# NUC1xx_registers register map
File version: 0.1
Registers are 32-bit, read-write, reset 0x0 unless marked. A register's access mark holds for its fields unless they carry their own. Offsets are from the block's base; [hi:lo] are bit positions; lines under a group give offsets from that group; {n}, {i} and the like mark numbered series.

## GPIO — Registers group
Base 0x50004180
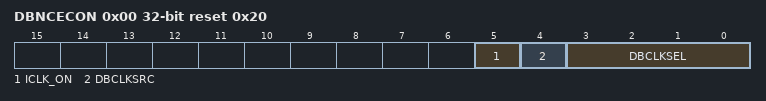
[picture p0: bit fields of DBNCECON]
0x00 DBNCECON reset 0x20 (reset mask 0xFFFFFFDF) — External Interrupt De-bounce Control
  [5] ICLK_ON — Interrupt clock On mode Set this bit to 0 will disable the interrupt generate circuit clock, if the pin[n] interrupt is disabled 1 = Interrupt generated circuit clock always enable 0 = Disable the clock if the GPIOA/B/C/D/E[n] interrupt is disabled
  [4] DBCLKSRC — De-bounce counter clock source select 1 = De-bounce counter clock source is the internal 10 KHz clock 0 = De-bounce counter clock source is the HCLK
  [3:0] DBCLKSEL — De-bounce sampling cycle selection DBCLKSEL Description 0 Sample interrupt input once per 1 clocks 1 Sample interrupt input once per 2 clocks 2 Sample interrupt input once per 4 clocks 3 Sample interrupt input once per 8 clocks 4 Sample interrupt input once per 16 clocks 5 Sample interrupt input once per 32 clocks 6 Sample interrupt input once per 64 clocks 7 Sample interrupt input once per 128 clocks 8 Sample interrupt input once per 256 clocks 9 Sample interrupt input once per 2*256 clocks 10 Sample interrupt input once per 4*256clocks 11 Sample interrupt input once per 8*256 clocks 12 Sample interrupt input once per 16*256 clocks 13 Sample interrupt input once per 32*256 clocks 14 Sample interrupt input once per 64*256 clocks 15 Sample interrupt input once per 128*256 clocks

## GPA_BITS — Registers group
Base 0x50004200
Same registers: GPB_BITS 0x50004240, GPC_BITS 0x50004280, GPD_BITS 0x500042C0, GPE_BITS 0x50004300
{0x0+4i} DOUT[{i}] (i=0..15) reset 0x1 — GPIO Port Pin I/O Bit Output Control
  [0] DOUT — GPIOxx I/O Pin Bit Output Control Set this bit can control one GPIO pin output value For example: write GPIOx0_DOUT will reflect the written value to bit GPIOx_DOUT[0], read GPIOx0_DOUT will return the value of GPIOx_PIN[0].
    0=low (Set corresponding GPIO bit to low); 1=high (Set corresponding GPIO bit to high)

## WDT — Registers group
Base 0x40004000
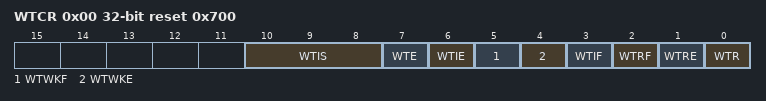
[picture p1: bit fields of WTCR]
0x00 WTCR reset 0x700 (reset mask 0xFFFFF8FF) — Watchdog Timer Control Register
  [10:8] WTIS — Watchdog Timer Interval Select (write protection bit) These three bits select the timeout interval for the Watchdog timer. WTIS Timeout Interval Selection Interrupt Period WTR Timeout Interval (WDT_CLK=12MHz) 000 2^4 * WDT_CLK (2^4 + 1024) * WDT_CLK 1.33 us ~ 86.67 us 001 2^6 * WDT_CLK (2^6 + 1024) * WDT_CLK 5.33 us ~ 90.67 us 010 2^8 * WDT_CLK (2^8 + 1024) * WDT_CLK 21.33 us ~ 106.67 us 011 2^10 * WDT_CLK (2^10 + 1024) * WDT_CLK 85.33 us ~ 170.67 us 100 2^12 * WDT_CLK (2^12 + 1024) * WDT_CLK 341.33 us ~ 426.67 us 101 2^14 * WDT_CLK (2^14 + 1024) * WDT_CLK 1.36 ms ~ 1.45 ms 110 2^16 * WDT_CLK (2^16 + 1024) * WDT_CLK 5.46 ms ~ 5.55 ms 111 2^18 * WDT_CLK (2^18 + 1024) * WDT_CLK 21.84 ms ~ 21.93 ms
  [7] WTE — Watchdog Timer Enable (write protection bit) 0 = Disable the Watchdog timer (This action will reset the internal counter) 1 = Enable the Watchdog timer
  [6] WTIE — Watchdog Timer Interrupt Enable (write protection bit) 0 = Disable the Watchdog timer interrupt 1 = Enable the Watchdog timer interrupt
  [5] WTWKF write-1-clears — Watchdog Timer Wakeup Flag If Watchdog timer causes CPU wakes up from power-down mode, this bit will be set to high. It must be cleared by software with a write 1 to this bit. 0 : Watchdog timer does not cause CPU wakeup. 1 : CPU wake up from sleep or power-down mode by Watchdog timeout.
  [4] WTWKE — Watchdog Timer Wakeup Function Enable bit (write protection bit) 0 : Disable Watchdog timer Wakeup CPU function. 1 : Enable the Wakeup function that Watchdog timer timeout can wake up CPU from power-down mode. Note: CHIP can wakeup by WDT only if WDT clock source select RC10K.
  [3] WTIF write-1-clears — Watchdog Timer Interrupt Flag If the Watchdog timer interrupt is enabled, then the hardware will set this bit to indicate that the Watchdog timer interrupt has occurred. 0 = Watchdog timer interrupt does not occur 1 = Watchdog timer interrupt occurs NOTE: This bit is cleared by writing 1 to this bit.
  [2] WTRF write-1-clears — Watchdog Timer Reset Flag When the Watchdog timer initiates a reset, the hardware will set this bit. This flag can be read by software to determine the source of reset. Software is responsible to clear it manually by writing 1 to it. If WTRE is disabled, then the Watchdog timer has no effect on this bit. 0 = Watchdog timer reset did not occur 1 = Watchdog timer reset occurs NOTE: This bit is cleared by writing 1 to this bit.
  [1] WTRE — Watchdog Timer Reset Enable (write protection bit) Setting this bit will enable the Watchdog timer reset function. 0 = Disable Watchdog timer reset function 1 = Enable Watchdog timer reset function
  [0] WTR wo — Clear Watchdog Timer (write protection bit) Set this bit will clear the Watchdog timer. 0 = Writing 0 to this bit has no effect 1 = Reset the contents of the Watchdog timer NOTE: This bit will auto clear after few clock cycle
